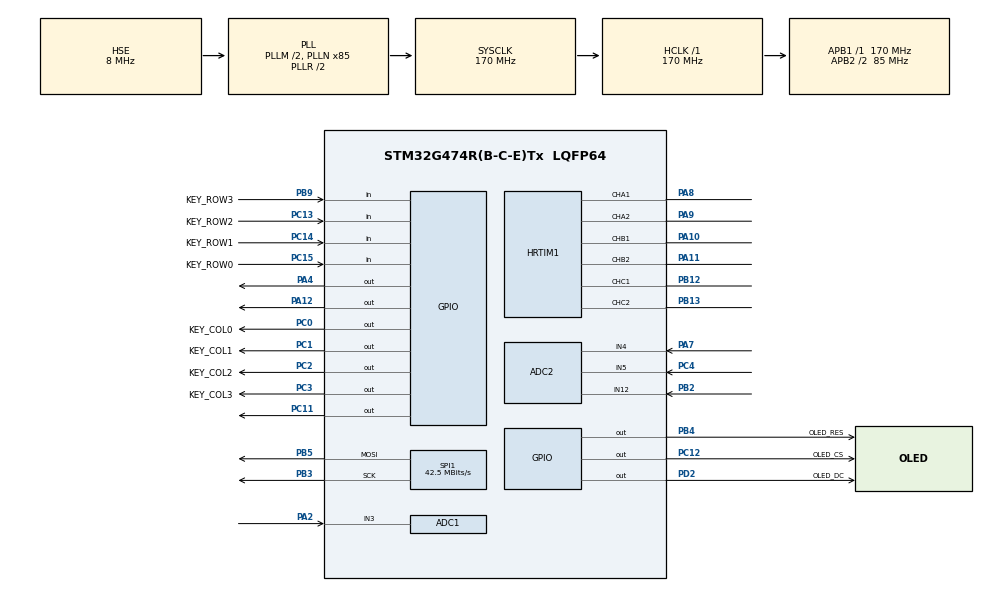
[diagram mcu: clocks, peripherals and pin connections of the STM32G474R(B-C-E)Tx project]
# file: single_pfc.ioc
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ADC1.EnableInjectedConversion=ENABLE
ADC1.EnableRegularConversion=DISABLE
ADC1.ExternalTrigInjecConv=ADC_EXTERNALTRIGINJEC_HRTIM_TRG2
ADC1.InjNumberOfConversion=1
ADC1.InjectedChannel-7\#ChannelInjectedConversion=ADC_CHANNEL_3
ADC1.InjectedOffsetNumber-7\#ChannelInjectedConversion=ADC_OFFSET_NONE
ADC1.InjectedRank-7\#ChannelInjectedConversion=1
ADC1.InjectedSamplingTime-7\#ChannelInjectedConversion=ADC_SAMPLETIME_24CYCLES_5
ADC1.Rank1_Channel=ADC_CHANNEL_3
ADC1.master=1
ADC2.EnableInjectedConversion=ENABLE
ADC2.EnableRegularConversion=DISABLE
ADC2.ExternalTrigInjecConv=ADC_EXTERNALTRIGINJEC_HRTIM_TRG2
ADC2.InjNumberOfConversion=3
ADC2.InjectedChannel-1\#ChannelInjectedConversion=ADC_CHANNEL_4
ADC2.InjectedChannel-2\#ChannelInjectedConversion=ADC_CHANNEL_5
ADC2.InjectedChannel-3\#ChannelInjectedConversion=ADC_CHANNEL_12
ADC2.InjectedOffsetNumber-1\#ChannelInjectedConversion=ADC_OFFSET_NONE
ADC2.InjectedOffsetNumber-2\#ChannelInjectedConversion=ADC_OFFSET_NONE
ADC2.InjectedOffsetNumber-3\#ChannelInjectedConversion=ADC_OFFSET_NONE
ADC2.InjectedRank-1\#ChannelInjectedConversion=1
ADC2.InjectedRank-2\#ChannelInjectedConversion=2
ADC2.InjectedRank-3\#ChannelInjectedConversion=3
ADC2.InjectedSamplingTime-1\#ChannelInjectedConversion=ADC_SAMPLETIME_24CYCLES_5
ADC2.InjectedSamplingTime-2\#ChannelInjectedConversion=ADC_SAMPLETIME_24CYCLES_5
ADC2.InjectedSamplingTime-3\#ChannelInjectedConversion=ADC_SAMPLETIME_24CYCLES_5
Dma.Request0=SPI1_TX
Dma.SPI1_TX.0.Direction=DMA_MEMORY_TO_PERIPH
Dma.SPI1_TX.0.EventEnable=DISABLE
Dma.SPI1_TX.0.Instance=DMA1_Channel1
Dma.SPI1_TX.0.MemDataAlignment=DMA_MDATAALIGN_BYTE
Dma.SPI1_TX.0.MemInc=DMA_MINC_ENABLE
Dma.SPI1_TX.0.Mode=DMA_NORMAL
Dma.SPI1_TX.0.PeriphDataAlignment=DMA_PDATAALIGN_BYTE
Dma.SPI1_TX.0.PeriphInc=DMA_PINC_DISABLE
Dma.SPI1_TX.0.Polarity=HAL_DMAMUX_REQ_GEN_RISING
Dma.SPI1_TX.0.Priority=DMA_PRIORITY_LOW
Dma.SPI1_TX.0.RequestNumber=1
Dma.SPI1_TX.0.SignalID=NONE
Dma.SPI1_TX.0.SyncEnable=DISABLE
Dma.SPI1_TX.0.SyncPolarity=HAL_DMAMUX_SYNC_NO_EVENT
Dma.SPI1_TX.0.SyncRequestNumber=1
Dma.SPI1_TX.0.SyncSignalID=NONE
HRTIM1.ADCTrigger2_Source1=HRTIM_ADCTRIGGEREVENT24_TIMERB_CMP2
HRTIM1.ADCTrigger_Id1=__NULL
HRTIM1.ADCTrigger_Id2=HRTIM_ADCTRIGGER_2
HRTIM1.CompareUnit1-MasterTimer=__NULL
HRTIM1.CompareUnit1-Output_TA1TA2=HRTIM_COMPAREUNIT_1
HRTIM1.CompareUnit1-Output_TB1TB2=HRTIM_COMPAREUNIT_1
HRTIM1.CompareUnit1-Output_TC1TC2=HRTIM_COMPAREUNIT_1
HRTIM1.CompareUnit2-MasterTimer=__NULL
HRTIM1.CompareUnit2-Output_TA1TA2=HRTIM_COMPAREUNIT_2
HRTIM1.CompareUnit2-Output_TB1TB2=HRTIM_COMPAREUNIT_2
HRTIM1.CompareUnit2-Output_TC1TC2=HRTIM_COMPAREUNIT_2
HRTIM1.CompareUnit3-MasterTimer=__NULL
HRTIM1.CompareUnit3-Output_TA1TA2=__NULL
HRTIM1.CompareValue1-Output_TA1TA2=1000
HRTIM1.CompareValue1-Output_TB1TB2=25000
HRTIM1.CompareValue1-Output_TC1TC2=25000
HRTIM1.CompareValue2-Output_TA1TA2=50000
HRTIM1.CompareValue2-Output_TB1TB2=50000
HRTIM1.CompareValue2-Output_TC1TC2=50000
HRTIM1.DeadTimeInsertion-Output_TA1TA2=HRTIM_TIMDEADTIMEINSERTION_ENABLED
HRTIM1.DeadTimeInsertion-Output_TB1TB2=HRTIM_TIMDEADTIMEINSERTION_ENABLED
HRTIM1.DeadTimeInsertion-Output_TC1TC2=HRTIM_TIMDEADTIMEINSERTION_ENABLED
HRTIM1.Event_EEV1=__NULL
HRTIM1.FallingValue-Output_TA1TA2=60
HRTIM1.FallingValue-Output_TB1TB2=60
HRTIM1.FallingValue-Output_TC1TC2=200
HRTIM1.IdleLevel1-Output_TA1TA2=HRTIM_OUTPUTIDLELEVEL_ACTIVE
HRTIM1.IdleLevel2-Output_TA1TA2=HRTIM_OUTPUTIDLELEVEL_INACTIVE
HRTIM1.IdleLevel2-Output_TB1TB2=HRTIM_OUTPUTIDLELEVEL_ACTIVE
HRTIM1.NumberADCTriggerSource2=1
HRTIM1.NumberResetSource1-Output_TA1TA2=1
HRTIM1.NumberResetSource1-Output_TB1TB2=1
HRTIM1.NumberResetSource1-Output_TC1TC2=1
HRTIM1.NumberResetSource2_TA=0
HRTIM1.NumberResetSource2_TB=0
HRTIM1.NumberResetTrigger-Output_TA1TA2=1
HRTIM1.NumberResetTrigger-Output_TB1TB2=1
HRTIM1.NumberResetTrigger-Output_TC1TC2=1
HRTIM1.NumberSetSource1-Output_TA1TA2=1
HRTIM1.NumberSetSource1-Output_TB1TB2=1
HRTIM1.NumberSetSource1-Output_TC1TC2=1
HRTIM1.NumberSetSource2_TA=0
HRTIM1.NumberSetSource2_TB=0
HRTIM1.ORingUpdateSource_ADCTrigger2=HRTIM_ADCTRIGGERUPDATE_TIMER_B
HRTIM1.Periode_MASTER=50000
HRTIM1.Periode_TA=50000
HRTIM1.Periode_TB=50000
HRTIM1.Periode_TC=50000
HRTIM1.Polarity1-Output_TA1TA2=HRTIM_OUTPUTPOLARITY_HIGH
HRTIM1.Polarity1-Output_TB1TB2=HRTIM_OUTPUTPOLARITY_LOW
HRTIM1.Polarity2-Output_TA1TA2=HRTIM_OUTPUTPOLARITY_HIGH
HRTIM1.Polarity2-Output_TB1TB2=HRTIM_OUTPUTPOLARITY_LOW
HRTIM1.PreloadEnable-MasterTimer=HRTIM_PRELOAD_ENABLED
HRTIM1.PreloadEnable-Output_TA1TA2=HRTIM_PRELOAD_ENABLED
HRTIM1.PreloadEnable-Output_TB1TB2=HRTIM_PRELOAD_ENABLED
HRTIM1.PreloadEnable-Output_TC1TC2=HRTIM_PRELOAD_ENABLED
HRTIM1.PrescalerRatio_MASTER=HRTIM_PRESCALERRATIO_MUL8
HRTIM1.PrescalerRatio_TA=HRTIM_PRESCALERRATIO_MUL16
HRTIM1.PrescalerRatio_TB=HRTIM_PRESCALERRATIO_MUL16
HRTIM1.PrescalerRatio_TC=HRTIM_PRESCALERRATIO_MUL16
HRTIM1.RepetitionUpdate-MasterTimer=HRTIM_UPDATEONREPETITION_DISABLED
HRTIM1.RepetitionUpdate-Output_TA1TA2=HRTIM_UPDATEONREPETITION_ENABLED
HRTIM1.RepetitionUpdate-Output_TB1TB2=HRTIM_UPDATEONREPETITION_ENABLED
HRTIM1.RepetitionUpdate-Output_TC1TC2=HRTIM_UPDATEONREPETITION_ENABLED
HRTIM1.ResetOutput1_Source1-Output_TA1TA2=HRTIM_OUTPUTRESET_TIMCMP1
HRTIM1.ResetOutput1_Source1-Output_TB1TB2=HRTIM_OUTPUTRESET_TIMCMP1
HRTIM1.ResetOutput1_Source1-Output_TC1TC2=HRTIM_OUTPUTRESET_TIMCMP1
HRTIM1.ResetTrigger1-Output_TA1TA2=HRTIM_TIMRESETTRIGGER_MASTER_PER
HRTIM1.ResetTrigger1-Output_TB1TB2=HRTIM_TIMRESETTRIGGER_MASTER_PER
HRTIM1.ResetTrigger1-Output_TC1TC2=HRTIM_TIMRESETTRIGGER_MASTER_PER
HRTIM1.RisingValue-Output_TA1TA2=60
HRTIM1.RisingValue-Output_TB1TB2=60
HRTIM1.RisingValue-Output_TC1TC2=60
HRTIM1.SetOutput1_Source1-Output_TA1TA2=HRTIM_OUTPUTSET_TIMCMP1
HRTIM1.SetOutput1_Source1-Output_TB1TB2=HRTIM_OUTPUTSET_TIMCMP1
HRTIM1.SetOutput1_Source1-Output_TC1TC2=HRTIM_OUTPUTSET_TIMCMP1
HRTIM1.StartOnSync-Output_TA1TA2=HRTIM_SYNCSTART_DISABLED
HRTIM1.StartOnSync-Output_TB1TB2=HRTIM_SYNCSTART_DISABLED
HRTIM1.SyncInputSource=HRTIM_SYNCINPUTSOURCE_INTERNALEVENT
HRTIM1.SyncOptions=HRTIM_SYNCOPTION_SLAVE
HRTIM1.UpDownMode-Output_TA1TA2=HRTIM_TIMERUPDOWNMODE_UPDOWN
HRTIM1.UpDownMode-Output_TB1TB2=HRTIM_TIMERUPDOWNMODE_UPDOWN
HRTIM1.UpDownMode-Output_TC1TC2=HRTIM_TIMERUPDOWNMODE_UPDOWN
HRTIM1.postscaler2=0
Mcu.Family=STM32G4
Mcu.Name=STM32G474R(B-C-E)Tx
Mcu.Package=LQFP64
NVIC.ADC1_2_IRQn=true\:0\:0\:false\:false\:true\:true\:true\:true
NVIC.DMA1_Channel1_IRQn=true\:0\:0\:false\:false\:true\:false\:true\:true
NVIC.PriorityGroup=NVIC_PRIORITYGROUP_4
PA10.Mode=Output_TB1TB2
PA10.Signal=HRTIM1_CHB1
PA11.Mode=Output_TB1TB2
PA11.Signal=HRTIM1_CHB2
PA12.GPIO_PuPd=GPIO_PULLUP
PA12.PinState=GPIO_PIN_SET
PA12.Signal=GPIO_Output
PA13.Mode=Serial_Wire
PA13.Signal=SYS_JTMS-SWDIO
PA14.Mode=Serial_Wire
PA14.Signal=SYS_JTCK-SWCLK
PA2.Mode=IN3-Single-Ended
PA2.Signal=ADC1_IN3
PA4.Signal=GPIO_Output
PA7.Mode=IN4-Single-Ended
PA7.Signal=ADC2_IN4
PA8.Mode=Output_TA1TA2
PA8.Signal=HRTIM1_CHA1
PA9.Mode=Output_TA1TA2
PA9.Signal=HRTIM1_CHA2
PB12.Mode=Output_TC1TC2
PB12.Signal=HRTIM1_CHC1
PB13.Mode=Output_TC1TC2
PB13.Signal=HRTIM1_CHC2
PB2.Mode=IN12-Single-Ended
PB2.Signal=ADC2_IN12
PB3.Mode=TX_Only_Simplex_Unidirect_Master
PB3.Signal=SPI1_SCK
PB4.GPIO_Label=OLED_RES
PB4.Signal=GPIO_Output
PB5.Mode=TX_Only_Simplex_Unidirect_Master
PB5.Signal=SPI1_MOSI
PB9.GPIO_Label=KEY_ROW3
PB9.GPIO_PuPd=GPIO_PULLDOWN
PB9.Signal=GPIO_Input
PC0.GPIO_Label=KEY_COL0
PC0.GPIO_PuPd=GPIO_PULLDOWN
PC0.GPIO_Speed=GPIO_SPEED_FREQ_VERY_HIGH
PC0.Signal=GPIO_Output
PC1.GPIO_Label=KEY_COL1
PC1.GPIO_PuPd=GPIO_PULLDOWN
PC1.GPIO_Speed=GPIO_SPEED_FREQ_VERY_HIGH
PC1.Signal=GPIO_Output
PC11.Signal=GPIO_Output
PC12.GPIO_Label=OLED_CS
PC12.Signal=GPIO_Output
PC13.GPIO_Label=KEY_ROW2
PC13.GPIO_PuPd=GPIO_PULLDOWN
PC13.Signal=GPIO_Input
PC14-OSC32_IN.GPIO_Label=KEY_ROW1
PC14-OSC32_IN.GPIO_PuPd=GPIO_PULLDOWN
PC14-OSC32_IN.Signal=GPIO_Input
PC15-OSC32_OUT.GPIO_Label=KEY_ROW0
PC15-OSC32_OUT.GPIO_PuPd=GPIO_PULLDOWN
PC15-OSC32_OUT.Signal=GPIO_Input
PC2.GPIO_Label=KEY_COL2
PC2.GPIO_PuPd=GPIO_PULLDOWN
PC2.GPIO_Speed=GPIO_SPEED_FREQ_VERY_HIGH
PC2.Signal=GPIO_Output
PC3.GPIO_Label=KEY_COL3
PC3.GPIO_PuPd=GPIO_PULLDOWN
PC3.GPIO_Speed=GPIO_SPEED_FREQ_VERY_HIGH
PC3.Signal=GPIO_Output
PC4.Mode=IN5-Single-Ended
PC4.Signal=ADC2_IN5
PD2.GPIO_Label=OLED_DC
PD2.Signal=GPIO_Output
PF0-OSC_IN.Mode=HSE-External-Oscillator
PF0-OSC_IN.Signal=RCC_OSC_IN
PF1-OSC_OUT.Mode=HSE-External-Oscillator
PF1-OSC_OUT.Signal=RCC_OSC_OUT
ProjectManager.HeapSize=0x200
ProjectManager.StackSize=0x400
ProjectManager.TargetToolchain=MDK-ARM V5.32
RCC.ADC12Freq_Value=170000000
RCC.ADC345Freq_Value=170000000
RCC.AHBFreq_Value=170000000
RCC.APB1Freq_Value=170000000
RCC.APB1TimFreq_Value=170000000
RCC.APB2CLKDivider=RCC_HCLK_DIV2
RCC.APB2Freq_Value=85000000
RCC.APB2TimFreq_Value=170000000
RCC.CortexFreq_Value=170000000
RCC.EXTERNAL_CLOCK_VALUE=12288000
RCC.HCLKFreq_Value=170000000
RCC.HSE_VALUE=8000000
RCC.HSI48_VALUE=48000000
RCC.HSI_VALUE=16000000
RCC.LSE_VALUE=32768
RCC.PLLM=RCC_PLLM_DIV2
RCC.PLLN=85
RCC.PLLSourceVirtual=RCC_PLLSOURCE_HSE
RCC.SYSCLKFreq_VALUE=170000000
RCC.SYSCLKSource=RCC_SYSCLKSOURCE_PLLCLK
RCC.USBFreq_Value=170000000
RCC.VCOOutputFreq_Value=340000000
SPI1.BaudRatePrescaler=SPI_BAUDRATEPRESCALER_2
SPI1.CalculateBaudRate=42.5 MBits/s
SPI1.DataSize=SPI_DATASIZE_8BIT
SPI1.Direction=SPI_DIRECTION_2LINES
SPI1.Mode=SPI_MODE_MASTER
SPI1.NSSPMode=SPI_NSS_PULSE_DISABLE
SPI1.VirtualType=VM_MASTER
STMicroelectronics.X-CUBE-ALGOBUILD.1.4.0.LibraryCcDSPOoLibraryJjDSPOoLibrary=true
VP_HRTIM1_VS_hrtimMasterTimerNoOutput.Mode=MasterTimer
VP_STMicroelectronics.X-CUBE-ALGOBUILD_VS_DSPOoLibraryJjLibrary_1.4.0_1.4.0.Mode=DSPOoLibraryJjLibrary
VP_SYS_VS_DBSignals.Mode=DisableDeadBatterySignals
VP_TIM1_VS_ClockSourceINT.Mode=Internal
board=custom

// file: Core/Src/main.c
/* USER CODE BEGIN Header */
/**
  ******************************************************************************
  * @file           : main.c
  * @brief          : Main program body
  ******************************************************************************
  * @attention
  *
  * Copyright (c) 2025 STMicroelectronics.
  * All rights reserved.
  *
  * This software is licensed under terms that can be found in the LICENSE file
  * in the root directory of this software component.
  * If no LICENSE file comes with this software, it is provided AS-IS.
  *
  ******************************************************************************
  */
/* USER CODE END Header */
#include "main.h"
#include "adc.h"
#include "dma.h"
#include "hrtim.h"
#include "spi.h"
#include "tim.h"
#include "gpio.h"

/* USER CODE BEGIN Includes */
#include "task.h"
/* USER CODE END Includes */

void SystemClock_Config(void);

int main(void)
{

  /* MCU Configuration--------------------------------------------------------*/

  /* Reset of all peripherals, Initializes the Flash interface and the Systick. */
  HAL_Init();

  /* Configure the system clock */
  SystemClock_Config();

  /* Initialize all configured peripherals */
  MX_GPIO_Init();
  MX_DMA_Init();
  MX_ADC1_Init();
  MX_HRTIM1_Init();
  MX_TIM1_Init();
  MX_ADC2_Init();
  MX_SPI1_Init();
  /* USER CODE BEGIN 2 */
  task_init();
  /* USER CODE END 2 */

  /* Infinite loop */
  /* USER CODE BEGIN WHILE */
  while (1)
  {
    task_run();
    /* USER CODE END WHILE */

  }
}

void SystemClock_Config(void)
{
  RCC_OscInitTypeDef RCC_OscInitStruct = {0};
  RCC_ClkInitTypeDef RCC_ClkInitStruct = {0};

  /** Configure the main internal regulator output voltage
  */
  HAL_PWREx_ControlVoltageScaling(PWR_REGULATOR_VOLTAGE_SCALE1_BOOST);

  /** Initializes the RCC Oscillators according to the specified parameters
  * in the RCC_OscInitTypeDef structure.
  */
  RCC_OscInitStruct.OscillatorType = RCC_OSCILLATORTYPE_HSE;
  RCC_OscInitStruct.HSEState = RCC_HSE_ON;
  RCC_OscInitStruct.PLL.PLLState = RCC_PLL_ON;
  RCC_OscInitStruct.PLL.PLLSource = RCC_PLLSOURCE_HSE;
  RCC_OscInitStruct.PLL.PLLM = RCC_PLLM_DIV2;
  RCC_OscInitStruct.PLL.PLLN = 85;
  RCC_OscInitStruct.PLL.PLLP = RCC_PLLP_DIV2;
  RCC_OscInitStruct.PLL.PLLQ = RCC_PLLQ_DIV2;
  RCC_OscInitStruct.PLL.PLLR = RCC_PLLR_DIV2;
  if (HAL_RCC_OscConfig(&RCC_OscInitStruct) != HAL_OK)
  {
    Error_Handler();
  }

  /** Initializes the CPU, AHB and APB buses clocks
  */
  RCC_ClkInitStruct.ClockType = RCC_CLOCKTYPE_HCLK|RCC_CLOCKTYPE_SYSCLK
                              |RCC_CLOCKTYPE_PCLK1|RCC_CLOCKTYPE_PCLK2;
  RCC_ClkInitStruct.SYSCLKSource = RCC_SYSCLKSOURCE_PLLCLK;
  RCC_ClkInitStruct.AHBCLKDivider = RCC_SYSCLK_DIV1;
  RCC_ClkInitStruct.APB1CLKDivider = RCC_HCLK_DIV1;
  RCC_ClkInitStruct.APB2CLKDivider = RCC_HCLK_DIV2;

  if (HAL_RCC_ClockConfig(&RCC_ClkInitStruct, FLASH_LATENCY_4) != HAL_OK)
  {
    Error_Handler();
  }
}

void Error_Handler(void)
{
  __disable_irq();
  while (1)
  {
  }
}
